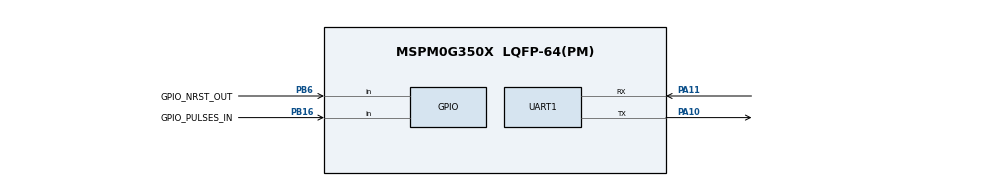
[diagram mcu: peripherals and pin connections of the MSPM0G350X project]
/**
 * @cliArgs --device "MSPM0G350X" --part "Default" --package "LQFP-64(PM)" --product "mspm0_sdk@2.03.00.08"
 * @versions {"tool":"1.22.0+3893"}
 */

/**
 * Import the modules used in this configuration.
 */
const GPIO   = scripting.addModule("/ti/driverlib/GPIO", {}, false);
const GPIO1  = GPIO.addInstance();
const GPIO2  = GPIO.addInstance();
const SYSCTL = scripting.addModule("/ti/driverlib/SYSCTL");
const TIMER  = scripting.addModule("/ti/driverlib/TIMER", {}, false);
const TIMER1 = TIMER.addInstance();
const UART   = scripting.addModule("/ti/driverlib/UART", {}, false);
const UART1  = UART.addInstance();

/**
 * Write custom configuration values to the imported modules.
 */
GPIO1.$name                                       = "GPIO_LEDS";
GPIO1.associatedPins.create(2);
GPIO1.associatedPins[0].$name                     = "USER_LED_1";
GPIO1.associatedPins[0].initialValue              = "SET";
GPIO1.associatedPins[0].launchPadShortcut         = "LED2RedEn";
GPIO1.associatedPins[1].$name                     = "USER_TEST";
GPIO1.associatedPins[1].initialValue              = "SET";
GPIO1.associatedPins[1].pin.$assignAllowConflicts = "PB3";

const Board = scripting.addModule("/ti/driverlib/Board", {}, false);

GPIO2.port                                  = "PORTB";
GPIO2.$name                                 = "GPIO_CLK_GRP";
GPIO2.associatedPins.create(3);
GPIO2.associatedPins[0].direction           = "INPUT";
GPIO2.associatedPins[0].ioStructure         = "SD";
GPIO2.associatedPins[0].interruptEn         = true;
GPIO2.associatedPins[0].polarity            = "RISE";
GPIO2.associatedPins[0].assignedPortSegment = "Lower";
GPIO2.associatedPins[0].assignedPin         = "0";
GPIO2.associatedPins[0].$name               = "GPIO_CLK_IN";
GPIO2.associatedPins[1].$name               = "GPIO_PULSES_IN";
GPIO2.associatedPins[1].direction           = "INPUT";
GPIO2.associatedPins[1].pin.$assign         = "PB16";
GPIO2.associatedPins[2].$name               = "GPIO_NRST_OUT";
GPIO2.associatedPins[2].direction           = "INPUT";
GPIO2.associatedPins[2].pin.$assign         = "PB6";

SYSCTL.validateClkStatus     = true;
SYSCTL.forceDefaultClkConfig = true;
SYSCTL.enableSYSOSCFCL       = true;
SYSCTL.enableROSC            = true;

TIMER1.$name              = "TIMER_0";
TIMER1.timerClkDiv        = 8;
TIMER1.timerClkSrc        = "LFCLK";
TIMER1.timerMode          = "PERIODIC";
TIMER1.interrupts         = ["ZERO"];
TIMER1.timerPeriod        = "1000 ms";
TIMER1.timerStartTimer    = true;
TIMER1.peripheral.$assign = "TIMG0";

UART1.$name                             = "UART_0";
UART1.rxFifoThreshold                   = "DL_UART_RX_FIFO_LEVEL_ONE_ENTRY";
UART1.enableFIFO                        = true;
UART1.txFifoThreshold                   = "DL_UART_TX_FIFO_LEVEL_ONE_ENTRY";
UART1.enabledDMATXTriggers              = "DL_UART_DMA_INTERRUPT_TX";
UART1.targetBaudRate                    = 921600;
UART1.enabledInterrupts                 = ["DMA_DONE_TX","EOT_DONE","RX"];
UART1.peripheral.$assign                = "UART0";
UART1.peripheral.rxPin.$assign          = "PA11";
UART1.peripheral.txPin.$assign          = "PA10";
UART1.txPinConfig.$name                 = "ti_driverlib_gpio_GPIOPinGeneric0";
UART1.rxPinConfig.$name                 = "ti_driverlib_gpio_GPIOPinGeneric1";
UART1.DMA_CHANNEL_TX.$name              = "DMA_CH0";
UART1.DMA_CHANNEL_TX.addressMode        = "b2f";
UART1.DMA_CHANNEL_TX.srcLength          = "BYTE";
UART1.DMA_CHANNEL_TX.dstLength          = "BYTE";
UART1.DMA_CHANNEL_TX.peripheral.$assign = "DMA_CH0";

/**
 * Pinmux solution for unlocked pins/peripherals. This ensures that minor changes to the automatic solver in a future
 * version of the tool will not impact the pinmux you originally saw.  These lines can be completely deleted in order to
 * re-solve from scratch.
 */
GPIO1.associatedPins[0].pin.$suggestSolution = "PB26";
Board.peripheral.$suggestSolution            = "DEBUGSS";
Board.peripheral.swclkPin.$suggestSolution   = "PA20";
Board.peripheral.swdioPin.$suggestSolution   = "PA19";
GPIO2.associatedPins[0].pin.$suggestSolution = "PB0";
SYSCTL.peripheral.$suggestSolution           = "SYSCTL";
SYSCTL.peripheral.roscPin.$suggestSolution   = "PA2";
